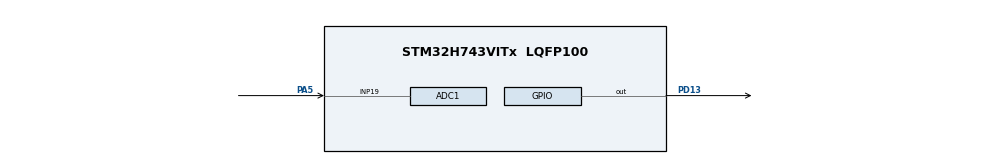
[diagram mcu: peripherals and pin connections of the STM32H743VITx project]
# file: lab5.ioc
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ADC1.Channel-0\#ChannelRegularConversion=ADC_CHANNEL_19
ADC1.NbrOfConversionFlag=1
ADC1.OffsetNumber-0\#ChannelRegularConversion=ADC_OFFSET_NONE
ADC1.OffsetSignedSaturation-0\#ChannelRegularConversion=DISABLE
ADC1.Rank-0\#ChannelRegularConversion=1
ADC1.Resolution=ADC_RESOLUTION_12B_OPT
ADC1.SamplingTime-0\#ChannelRegularConversion=ADC_SAMPLETIME_1CYCLE_5
ADC1.master=1
CORTEX_M7.default_mode_Activation=1
Mcu.Family=STM32H7
Mcu.Name=STM32H743VITx
Mcu.Package=LQFP100
NVIC.PriorityGroup=NVIC_PRIORITYGROUP_4
PA5.Signal=ADCx_INP19
PD13.Signal=GPIO_Output
ProjectManager.HeapSize=0x200
ProjectManager.StackSize=0x400
ProjectManager.TargetToolchain=STM32CubeIDE
RCC.ADCFreq_Value=80000000
RCC.APB1Freq_Value=64000000
RCC.APB2Freq_Value=64000000
RCC.APB3Freq_Value=64000000
RCC.APB4Freq_Value=64000000
RCC.CortexFreq_Value=64000000
RCC.DIVM2=4
RCC.DIVN2=10
RCC.HCLKFreq_Value=64000000
RCC.PLL2FRACN=0
RCC.SYSCLKFreq_VALUE=64000000
RCC.USBFreq_Value=129000000
SH.ADCx_INP19.0=ADC1_INP19,IN19-Single-Ended
VP_MEMORYMAP_VS_MEMORYMAP.Mode=CurAppReg
board=custom

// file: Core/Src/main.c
/* USER CODE BEGIN Header */
/**
  ******************************************************************************
  * @file           : main.c
  * @brief          : Main program body
  ******************************************************************************
  * @attention
  *
  * Copyright (c) 2026 STMicroelectronics.
  * All rights reserved.
  *
  * This software is licensed under terms that can be found in the LICENSE file
  * in the root directory of this software component.
  * If no LICENSE file comes with this software, it is provided AS-IS.
  *
  ******************************************************************************
  */
/* USER CODE END Header */
#include "main.h"

ADC_HandleTypeDef hadc1;

/* USER CODE BEGIN PV */
uint32_t adcValue = 0;
float voltage = 0.0f;
uint32_t previous_adc_millis = 0;
/* USER CODE END PV */

void SystemClock_Config(void);
static void MPU_Config(void);
static void MX_GPIO_Init(void);
static void MX_ADC1_Init(void);

int main(void)
{

  /* MPU Configuration--------------------------------------------------------*/
  MPU_Config();

  /* MCU Configuration--------------------------------------------------------*/

  /* Reset of all peripherals, Initializes the Flash interface and the Systick. */
  HAL_Init();

  /* Configure the system clock */
  SystemClock_Config();

  /* Initialize all configured peripherals */
  MX_GPIO_Init();
  MX_ADC1_Init();
  /* USER CODE BEGIN 2 */
  HAL_ADCEx_Calibration_Start(&hadc1, ADC_CALIB_OFFSET, ADC_SINGLE_ENDED);
  /* USER CODE END 2 */

  /* Infinite loop */
  while (1)
  {

    /* USER CODE BEGIN 3 */
	  uint32_t current_millis = HAL_GetTick();
	      // Опитуємо АЦП кожні 100 мс (10 разів на секунду)
	      if ((current_millis - previous_adc_millis) >= 100)
	      {
	          previous_adc_millis = current_millis;
	          HAL_ADC_Start(&hadc1); // Запускаємо перетворення
	          if (HAL_ADC_PollForConversion(&hadc1, 5) == HAL_OK) // Чекаємо завершення перетворення (максимум 5 мс)
	          {
	              // Зчитуємо значення АЦП
	              adcValue = HAL_ADC_GetValue(&hadc1);
	              // Перетворюємо цифровий код у напругу
	              // (формула для 12-бітної роздільної здатності: 2^12 = 4096)
	              voltage = (adcValue * 3.3f) / 4096.0f;
	              // Логіка порогового керування
	              if (voltage > 1.7f)
	              {
	                  HAL_GPIO_WritePin(GPIOD, GPIO_PIN_13, GPIO_PIN_SET);   // Напруга > 1.7 В: Світить
	              }
	              else
	              {
	                  HAL_GPIO_WritePin(GPIOD, GPIO_PIN_13, GPIO_PIN_RESET); // Напруга <= 1.7 В: Вимкнено
	              }
	          }
	          HAL_ADC_Stop(&hadc1);// Зупиняємо АЦП до наступного циклу
	      }
  }
  /* USER CODE END 3 */
}

void SystemClock_Config(void)
{
  RCC_OscInitTypeDef RCC_OscInitStruct = {0};
  RCC_ClkInitTypeDef RCC_ClkInitStruct = {0};

  /** Supply configuration update enable
  */
  HAL_PWREx_ConfigSupply(PWR_LDO_SUPPLY);

  /** Configure the main internal regulator output voltage
  */
  __HAL_PWR_VOLTAGESCALING_CONFIG(PWR_REGULATOR_VOLTAGE_SCALE3);

  while(!__HAL_PWR_GET_FLAG(PWR_FLAG_VOSRDY)) {}

  /** Macro to configure the PLL clock source
  */
  __HAL_RCC_PLL_PLLSOURCE_CONFIG(RCC_PLLSOURCE_HSI);

  /** Initializes the RCC Oscillators according to the specified parameters
  * in the RCC_OscInitTypeDef structure.
  */
  RCC_OscInitStruct.OscillatorType = RCC_OSCILLATORTYPE_HSI;
  RCC_OscInitStruct.HSIState = RCC_HSI_DIV1;
  RCC_OscInitStruct.HSICalibrationValue = RCC_HSICALIBRATION_DEFAULT;
  RCC_OscInitStruct.PLL.PLLState = RCC_PLL_NONE;
  if (HAL_RCC_OscConfig(&RCC_OscInitStruct) != HAL_OK)
  {
    Error_Handler();
  }

  /** Initializes the CPU, AHB and APB buses clocks
  */
  RCC_ClkInitStruct.ClockType = RCC_CLOCKTYPE_HCLK|RCC_CLOCKTYPE_SYSCLK
                              |RCC_CLOCKTYPE_PCLK1|RCC_CLOCKTYPE_PCLK2
                              |RCC_CLOCKTYPE_D3PCLK1|RCC_CLOCKTYPE_D1PCLK1;
  RCC_ClkInitStruct.SYSCLKSource = RCC_SYSCLKSOURCE_HSI;
  RCC_ClkInitStruct.SYSCLKDivider = RCC_SYSCLK_DIV1;
  RCC_ClkInitStruct.AHBCLKDivider = RCC_HCLK_DIV1;
  RCC_ClkInitStruct.APB3CLKDivider = RCC_APB3_DIV1;
  RCC_ClkInitStruct.APB1CLKDivider = RCC_APB1_DIV1;
  RCC_ClkInitStruct.APB2CLKDivider = RCC_APB2_DIV1;
  RCC_ClkInitStruct.APB4CLKDivider = RCC_APB4_DIV1;

  if (HAL_RCC_ClockConfig(&RCC_ClkInitStruct, FLASH_LATENCY_1) != HAL_OK)
  {
    Error_Handler();
  }
}

static void MX_ADC1_Init(void)
{

  ADC_MultiModeTypeDef multimode = {0};
  ADC_ChannelConfTypeDef sConfig = {0};

  /** Common config
  */
  hadc1.Instance = ADC1;
  hadc1.Init.ClockPrescaler = ADC_CLOCK_ASYNC_DIV2;
  hadc1.Init.Resolution = ADC_RESOLUTION_12B_OPT;
  hadc1.Init.ScanConvMode = ADC_SCAN_DISABLE;
  hadc1.Init.EOCSelection = ADC_EOC_SINGLE_CONV;
  hadc1.Init.LowPowerAutoWait = DISABLE;
  hadc1.Init.ContinuousConvMode = DISABLE;
  hadc1.Init.NbrOfConversion = 1;
  hadc1.Init.DiscontinuousConvMode = DISABLE;
  hadc1.Init.ExternalTrigConv = ADC_SOFTWARE_START;
  hadc1.Init.ExternalTrigConvEdge = ADC_EXTERNALTRIGCONVEDGE_NONE;
  hadc1.Init.ConversionDataManagement = ADC_CONVERSIONDATA_DR;
  hadc1.Init.Overrun = ADC_OVR_DATA_PRESERVED;
  hadc1.Init.LeftBitShift = ADC_LEFTBITSHIFT_NONE;
  hadc1.Init.OversamplingMode = DISABLE;
  hadc1.Init.Oversampling.Ratio = 1;
  if (HAL_ADC_Init(&hadc1) != HAL_OK)
  {
    Error_Handler();
  }

  /** Configure the ADC multi-mode
  */
  multimode.Mode = ADC_MODE_INDEPENDENT;
  if (HAL_ADCEx_MultiModeConfigChannel(&hadc1, &multimode) != HAL_OK)
  {
    Error_Handler();
  }

  /** Configure Regular Channel
  */
  sConfig.Channel = ADC_CHANNEL_19;
  sConfig.Rank = ADC_REGULAR_RANK_1;
  sConfig.SamplingTime = ADC_SAMPLETIME_1CYCLE_5;
  sConfig.SingleDiff = ADC_SINGLE_ENDED;
  sConfig.OffsetNumber = ADC_OFFSET_NONE;
  sConfig.Offset = 0;
  sConfig.OffsetSignedSaturation = DISABLE;
  if (HAL_ADC_ConfigChannel(&hadc1, &sConfig) != HAL_OK)
  {
    Error_Handler();
  }

}

static void MX_GPIO_Init(void)
{
  GPIO_InitTypeDef GPIO_InitStruct = {0};

  /* GPIO Ports Clock Enable */
  __HAL_RCC_GPIOA_CLK_ENABLE();
  __HAL_RCC_GPIOD_CLK_ENABLE();

  /*Configure GPIO pin Output Level */
  HAL_GPIO_WritePin(GPIOD, GPIO_PIN_13, GPIO_PIN_RESET);

  /*Configure GPIO pin : PD13 */
  GPIO_InitStruct.Pin = GPIO_PIN_13;
  GPIO_InitStruct.Mode = GPIO_MODE_OUTPUT_PP;
  GPIO_InitStruct.Pull = GPIO_NOPULL;
  GPIO_InitStruct.Speed = GPIO_SPEED_FREQ_LOW;
  HAL_GPIO_Init(GPIOD, &GPIO_InitStruct);

}

 /* MPU Configuration */

void MPU_Config(void)
{
  MPU_Region_InitTypeDef MPU_InitStruct = {0};

  /* Disables the MPU */
  HAL_MPU_Disable();

  /** Initializes and configures the Region and the memory to be protected
  */
  MPU_InitStruct.Enable = MPU_REGION_ENABLE;
  MPU_InitStruct.Number = MPU_REGION_NUMBER0;
  MPU_InitStruct.BaseAddress = 0x0;
  MPU_InitStruct.Size = MPU_REGION_SIZE_4GB;
  MPU_InitStruct.SubRegionDisable = 0x87;
  MPU_InitStruct.TypeExtField = MPU_TEX_LEVEL0;
  MPU_InitStruct.AccessPermission = MPU_REGION_NO_ACCESS;
  MPU_InitStruct.DisableExec = MPU_INSTRUCTION_ACCESS_DISABLE;
  MPU_InitStruct.IsShareable = MPU_ACCESS_SHAREABLE;
  MPU_InitStruct.IsCacheable = MPU_ACCESS_NOT_CACHEABLE;
  MPU_InitStruct.IsBufferable = MPU_ACCESS_NOT_BUFFERABLE;

  HAL_MPU_ConfigRegion(&MPU_InitStruct);
  /* Enables the MPU */
  HAL_MPU_Enable(MPU_PRIVILEGED_DEFAULT);

}

void Error_Handler(void)
{
  __disable_irq();
  while (1)
  {
  }
}
